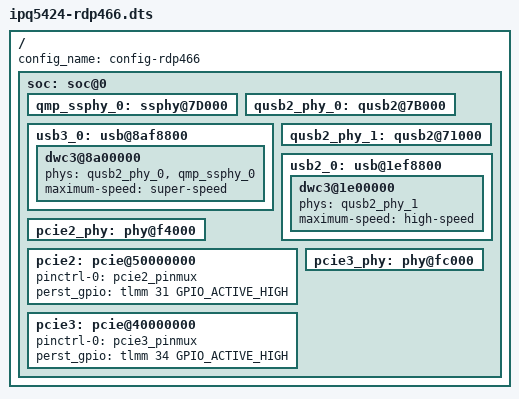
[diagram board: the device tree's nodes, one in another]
// SPDX-License-Identifier: GPL-2.0-only
/*
* Copyright (c) 2023-2024, Qualcomm Innovation Center, Inc. All rights reserved.
*/

#include "ipq5424-default.dts"

/ {
	config_name = "config-rdp466";

	soc: soc@0 {
		qmp_ssphy_0: ssphy@7D000 {
			status = "okay";
		};

		qusb2_phy_0: qusb2@7B000 {
			status = "okay";
		};

		usb3_0: usb@8af8800 {
			status = "okay";

			dwc3@8a00000 {
				phys = <&qusb2_phy_0>, <&qmp_ssphy_0>;
				phy-names = "usb2-phy", "usb3-phy";
				maximum-speed = "super-speed";
			};
		};

		qusb2_phy_1: qusb2@71000 {
			status = "okay";
		};

		usb2_0: usb@1ef8800 {
			status = "okay";

			dwc3@1e00000 {
				phys = <&qusb2_phy_1>;
				phy-names = "usb2-phy";
				maximum-speed = "high-speed";
			};
		};

		pcie2_phy: phy@f4000 {
			status = "okay";
		};

		pcie2: pcie@50000000 {
			pinctrl-names = "default";
			pinctrl-0 = <&pcie2_pinmux>;
			perst_gpio = <&tlmm 31 GPIO_ACTIVE_HIGH>;
			status = "okay";
		};

		pcie3_phy: phy@fc000 {
			status = "okay";
		};

		pcie3: pcie@40000000 {
			pinctrl-names = "default";
			pinctrl-0 = <&pcie3_pinmux>;
			perst_gpio = <&tlmm 34 GPIO_ACTIVE_HIGH>;
			status = "okay";
		};
	};
};
